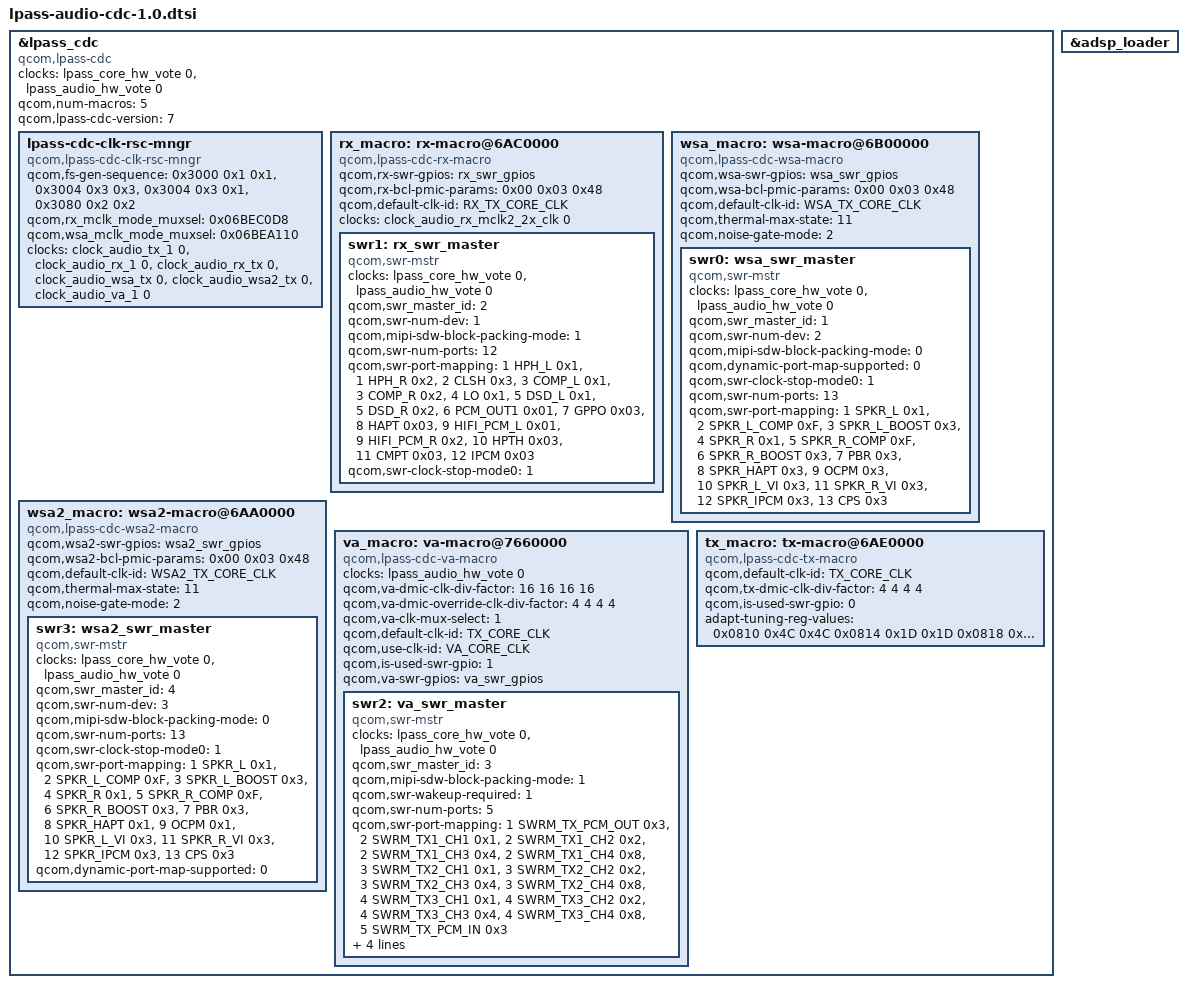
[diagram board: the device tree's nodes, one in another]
//
/* Copyright (c) Qualcomm Technologies, Inc. and/or its subsidiaries.
 * SPDX-License-Identifier: BSD-3-Clause-Clear
 */

#include <bindings/qcom,audio-ext-clk.h>
#include <bindings/qcom,lpass-cdc-clk-rsc.h>
#include <bindings/audio-codec-port-types.h>
#include <dt-bindings/interrupt-controller/arm-gic.h>
#include "lpass-audio-clk.dtsi"

&lpass_cdc {
		compatible = "qcom,lpass-cdc";
		#address-cells = <1>;
		#size-cells = <1>;
		clock-names = "lpass_core_hw_vote",
				"lpass_audio_hw_vote";
		clocks = <&lpass_core_hw_vote 0>,
				<&lpass_audio_hw_vote 0>;
		qcom,num-macros = <5>;
		qcom,lpass-cdc-version = <7>;
		lpass-cdc-clk-rsc-mngr {
			compatible = "qcom,lpass-cdc-clk-rsc-mngr";
			qcom,fs-gen-sequence = <0x3000 0x1 0x1>, <0x3004 0x3 0x3>,
					<0x3004 0x3 0x1>, <0x3080 0x2 0x2>;
			qcom,rx_mclk_mode_muxsel = <0x06BEC0D8>;
			qcom,wsa_mclk_mode_muxsel = <0x06BEA110>;
			clock-names = "tx_core_clk", "rx_core_clk",
				"rx_tx_core_clk", "wsa_tx_core_clk",
				"wsa2_tx_core_clk", "va_core_clk";
			clocks = <&clock_audio_tx_1 0>, <&clock_audio_rx_1 0>,
			<&clock_audio_rx_tx 0>, <&clock_audio_wsa_tx 0>,
			<&clock_audio_wsa2_tx 0>, <&clock_audio_va_1 0>;
		};

		rx_macro: rx-macro@6AC0000 {
			compatible = "qcom,lpass-cdc-rx-macro";
			qcom,rx-swr-gpios = <&rx_swr_gpios>;
			qcom,rx-bcl-pmic-params = /bits/ 8 <0x00 0x03 0x48>;
			qcom,default-clk-id = <RX_TX_CORE_CLK>;
			clock-names = "rx_mclk2_2x_clk";
			clocks = <&clock_audio_rx_mclk2_2x_clk 0>;
			swr1: rx_swr_master {
				compatible = "qcom,swr-mstr";
				#address-cells = <2>;
				#size-cells = <0>;
				clock-names = "lpass_core_hw_vote",
						"lpass_audio_hw_vote";
				clocks = <&lpass_core_hw_vote 0>,
					<&lpass_audio_hw_vote 0>;
				qcom,swr_master_id = <2>;
				qcom,swr-num-dev = <1>;
				qcom,mipi-sdw-block-packing-mode = <1>;
				interrupt-names = "swr_master_irq";
				qcom,swr-num-ports = <12>;
				qcom,swr-port-mapping = <1 HPH_L 0x1>,
					<1 HPH_R 0x2>, <2 CLSH 0x3>,
					<3 COMP_L 0x1>, <3 COMP_R 0x2>,
					<4 LO 0x1>, <5 DSD_L 0x1>,
					<5 DSD_R 0x2>, <6 PCM_OUT1 0x01>,
					<7 GPPO 0x03>, <8 HAPT 0x03>,
					<9 HIFI_PCM_L 0x01>, <9 HIFI_PCM_R 0x2>,
					<10 HPTH 0x03>, <11 CMPT 0x03>, <12 IPCM 0x03>;
				qcom,swr-clock-stop-mode0 = <1>;
			};
		};

		wsa_macro: wsa-macro@6B00000 {
			compatible = "qcom,lpass-cdc-wsa-macro";
			qcom,wsa-swr-gpios = <&wsa_swr_gpios>;
			qcom,wsa-bcl-pmic-params = /bits/ 8 <0x00 0x03 0x48>;
			qcom,default-clk-id = <WSA_TX_CORE_CLK>;
			qcom,thermal-max-state = <11>;
			qcom,noise-gate-mode = <2>;
			#cooling-cells = <2>;

			swr0: wsa_swr_master {
				compatible = "qcom,swr-mstr";
				#address-cells = <2>;
				#size-cells = <0>;
				clock-names = "lpass_core_hw_vote",
					"lpass_audio_hw_vote";
				clocks = <&lpass_core_hw_vote 0>,
					<&lpass_audio_hw_vote 0>;
				qcom,swr_master_id = <1>;
				qcom,swr-num-dev = <2>;
				qcom,mipi-sdw-block-packing-mode = <0>;
				qcom,dynamic-port-map-supported = <0>;
				qcom,swr-clock-stop-mode0 = <1>;
				qcom,swr-num-ports = <13>;
				qcom,swr-port-mapping = <1 SPKR_L 0x1>,
					<2 SPKR_L_COMP 0xF>, <3 SPKR_L_BOOST 0x3>,
					<4 SPKR_R 0x1>, <5 SPKR_R_COMP 0xF>,
					<6 SPKR_R_BOOST 0x3>, <7 PBR 0x3>,
					<8 SPKR_HAPT 0x3>, <9 OCPM 0x3>,
					<10 SPKR_L_VI 0x3>, <11 SPKR_R_VI 0x3>,
					<12 SPKR_IPCM 0x3>, <13 CPS 0x3>;
				interrupt-names = "swr_master_irq";

			};
		};

		wsa2_macro: wsa2-macro@6AA0000 {
			compatible = "qcom,lpass-cdc-wsa2-macro";
			qcom,wsa2-swr-gpios = <&wsa2_swr_gpios>;
			qcom,wsa2-bcl-pmic-params = /bits/ 8 <0x00 0x03 0x48>;
			qcom,default-clk-id = <WSA2_TX_CORE_CLK>;
			qcom,thermal-max-state = <11>;
			qcom,noise-gate-mode = <2>;
			#cooling-cells = <2>;
			swr3: wsa2_swr_master {
				compatible = "qcom,swr-mstr";
				#address-cells = <2>;
				#size-cells = <0>;
				clock-names = "lpass_core_hw_vote",
						"lpass_audio_hw_vote";
				clocks = <&lpass_core_hw_vote 0>,
						<&lpass_audio_hw_vote 0>;
				qcom,swr_master_id = <4>;
				qcom,swr-num-dev = <3>;
				qcom,mipi-sdw-block-packing-mode = <0>;
				interrupt-names = "swr_master_irq";
				qcom,swr-num-ports = <13>;
				qcom,swr-clock-stop-mode0 = <1>;
				qcom,swr-port-mapping = <1 SPKR_L 0x1>,
					<2 SPKR_L_COMP 0xF>, <3 SPKR_L_BOOST 0x3>,
					<4 SPKR_R 0x1>, <5 SPKR_R_COMP 0xF>,
					<6 SPKR_R_BOOST 0x3>, <7 PBR 0x3>,
					<8 SPKR_HAPT 0x1>, <9 OCPM 0x1>,
					<10 SPKR_L_VI 0x3>, <11 SPKR_R_VI 0x3>,
					<12 SPKR_IPCM 0x3>, <13 CPS 0x3>;
				qcom,dynamic-port-map-supported = <0>;
			};
		};

		va_macro: va-macro@7660000 {
			compatible = "qcom,lpass-cdc-va-macro";
			clock-names = "lpass_audio_hw_vote";
			clocks = <&lpass_audio_hw_vote 0>;
		/*
		 * Clk divding factors for each DMIC pair.
		 * Valid entries for each DMIC pair:
		 *	2, 3, 4, 6, 8, 16
		 *
		 * These factors are translated to corresponding config values
		 *  for the following registers,
		 *   -- LPASS_VA_TOP_CSR_DMIC0_CTL,
		 *   -- LPASS_VA_TOP_CSR_DMIC1_CTL,
		 *   -- LPASS_VA_TOP_CSR_DMIC2_CTL,
		 *   -- LPASS_VA_TOP_CSR_DMIC3_CTL,
		 */
			qcom,va-dmic-clk-div-factor = <16 16 16 16>;
		/* Property to override the qcom,va-dmic-clk-div-factor
		 * for sampling rates hgher than 16kHz.
		 */
			qcom,va-dmic-override-clk-div-factor = <4 4 4 4>;
			qcom,va-clk-mux-select = <1>;
			qcom,default-clk-id = <TX_CORE_CLK>;
			qcom,use-clk-id = <VA_CORE_CLK>;
			qcom,is-used-swr-gpio = <1>;
			qcom,va-swr-gpios = <&va_swr_gpios>;
			swr2: va_swr_master {
				compatible = "qcom,swr-mstr";
				#address-cells = <2>;
				#size-cells = <0>;
				clock-names = "lpass_core_hw_vote",
						"lpass_audio_hw_vote";
				clocks = <&lpass_core_hw_vote 0>,
					<&lpass_audio_hw_vote 0>;
				qcom,swr_master_id = <3>;
				qcom,mipi-sdw-block-packing-mode = <1>;
				qcom,swr-wakeup-required = <1>;
				qcom,swr-num-ports = <5>;

				interrupt-names = "swr_master_irq", "swr_wake_irq";
				qcom,swr-port-mapping = <1 SWRM_TX_PCM_OUT 0x3>,
						<2 SWRM_TX1_CH1 0x1>, <2 SWRM_TX1_CH2 0x2>,
						<2 SWRM_TX1_CH3 0x4>, <2 SWRM_TX1_CH4 0x8>,
						<3 SWRM_TX2_CH1 0x1>, <3 SWRM_TX2_CH2 0x2>,
						<3 SWRM_TX2_CH3 0x4>, <3 SWRM_TX2_CH4 0x8>,
						<4 SWRM_TX3_CH1 0x1>, <4 SWRM_TX3_CH2 0x2>,
						<4 SWRM_TX3_CH3 0x4>, <4 SWRM_TX3_CH4 0x8>,
						<5 SWRM_TX_PCM_IN 0x3>;
				qcom,swr-num-dev = <5>;
				qcom,swr-clock-stop-mode0 = <1>;
				qcom,swr-mstr-irq-wakeup-capable = <1>;
				qcom,is-always-on = <1>;
			};
		};

		tx_macro: tx-macro@6AE0000 {
			compatible = "qcom,lpass-cdc-tx-macro";
			qcom,default-clk-id = <TX_CORE_CLK>;
		/*
		 * Clk divding factors for each DMIC pair.
		 * Valid entries for each DMIC pair:
		 *	2, 3, 4, 6, 8, 16
		 *
		 * These factors are translated to corresponding config values
		 *  for the following registers,
		 *   -- LPASS_VA_TOP_CSR_DMIC0_CTL,
		 *   -- LPASS_VA_TOP_CSR_DMIC1_CTL,
		 *   -- LPASS_VA_TOP_CSR_DMIC2_CTL,
		 *   -- LPASS_VA_TOP_CSR_DMIC3_CTL,
		 */
			qcom,tx-dmic-clk-div-factor = <4 4 4 4>;
			qcom,is-used-swr-gpio = <0>;
		/* Adapt block tuning registers and its values.
		 * < adapt_reg_address msm_mic/swr_mic_value hs_mic_value >
		 */
			adapt-tuning-reg-values = < 0x0810 0x4C 0x4C
						0x0814 0x1D 0x1D
						0x0818 0x7C 0x7C
						0x081C 0x3C 0x3C
						0x0820 0x67 0x67
						0x0824 0x16 0x16
						0x0828 0x03 0x03>;
		};
};
&adsp_loader {
	status = "ok";
};
